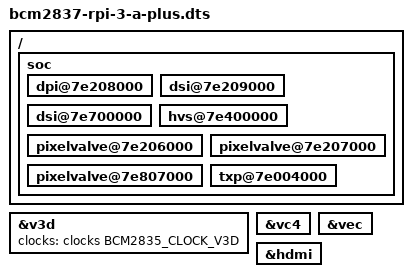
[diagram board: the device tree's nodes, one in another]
/* $NetBSD: $ */

/*-
 * Copyright (c) 2022 Robert Swindells <rjs@fdy2.co.uk>
 * All rights reserved.
 *
 * Redistribution and use in source and binary forms, with or without
 * modification, are permitted provided that the following conditions
 * are met:
 * 1. Redistributions of source code must retain the above copyright
 *    notice, this list of conditions and the following disclaimer.
 * 2. Redistributions in binary form must reproduce the above copyright
 *    notice, this list of conditions and the following disclaimer in the
 *    documentation and/or other materials provided with the distribution.
 *
 * THIS SOFTWARE IS PROVIDED BY THE AUTHOR ``AS IS'' AND ANY EXPRESS OR
 * IMPLIED WARRANTIES, INCLUDING, BUT NOT LIMITED TO, THE IMPLIED WARRANTIES
 * OF MERCHANTABILITY AND FITNESS FOR A PARTICULAR PURPOSE ARE DISCLAIMED.
 * IN NO EVENT SHALL THE AUTHOR BE LIABLE FOR ANY DIRECT, INDIRECT,
 * INCIDENTAL, SPECIAL, EXEMPLARY, OR CONSEQUENTIAL DAMAGES (INCLUDING,
 * BUT NOT LIMITED TO, PROCUREMENT OF SUBSTITUTE GOODS OR SERVICES;
 * LOSS OF USE, DATA, OR PROFITS; OR BUSINESS INTERRUPTION) HOWEVER CAUSED
 * AND ON ANY THEORY OF LIABILITY, WHETHER IN CONTRACT, STRICT LIABILITY,
 * OR TORT (INCLUDING NEGLIGENCE OR OTHERWISE) ARISING IN ANY WAY
 * OUT OF THE USE OF THIS SOFTWARE, EVEN IF ADVISED OF THE POSSIBILITY OF
 * SUCH DAMAGE.
 */

#include "../../../external/gpl2/dts/dist/arch/arm/boot/dts/bcm2837-rpi-3-a-plus.dts"

/ {
	soc {
		dpi@7e208000 {
			status = "okay";
		};
		dsi@7e209000 {
			status = "okay";
		};
		dsi@7e700000 {
			status = "okay";
		};
		hvs@7e400000 {
			status = "okay";
		};
		pixelvalve@7e206000 {
			status = "okay";
		};
		pixelvalve@7e207000 {
			status = "okay";
		};
		pixelvalve@7e807000 {
			status = "okay";
		};
		txp@7e004000 {
			status = "okay";
		};
	};
};

&v3d {
	clocks = <&clocks BCM2835_CLOCK_V3D>;
	clock-names = "v3d";
	status = "okay";
};

&vc4 {
	status = "okay";
};

&vec {
	status = "okay";
};

&hdmi {
	status = "okay";
};
